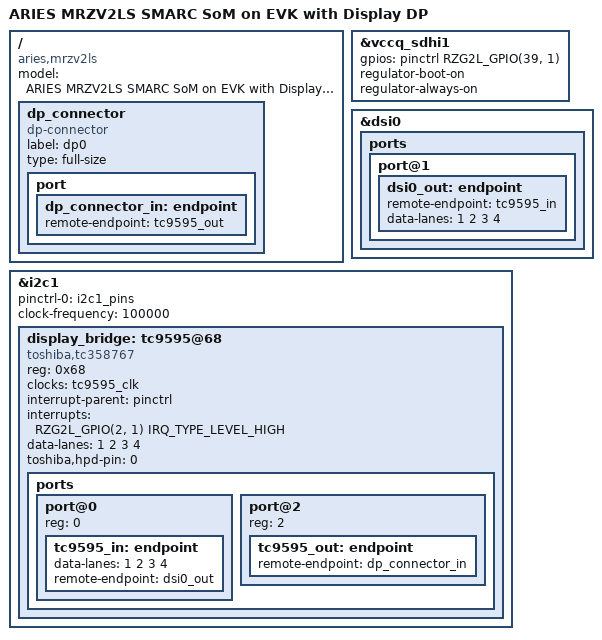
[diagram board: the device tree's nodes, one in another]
// SPDX-License-Identifier: GPL-2.0
/*
 * Device Tree Source for the MRZG2LS Single A55 SMARC SOM/CARRIER
 *
 * Copyright (C) 2021 Renesas Electronics Corp.
 * Copyright (C) 2023 ARIES Embedded
 */

/dts-v1/;
#include "../renesas/r9a07g054l2.dtsi"
#include "mrzg2ls-som.dtsi"
#include "mrzg2ls-pinfunction.dtsi"
#include "msrz-smarc-common.dtsi"
#include "mrzv2ls.dtsi"

/ {
	model = "ARIES MRZV2LS SMARC SoM on EVK with Display DP";
	compatible = "aries,mrzv2ls", "renesas,r9a07g054l2", "renesas,r9a07g054";

	dp_connector {
		compatible = "dp-connector";
		label = "dp0";
		type = "full-size";

		port {
			dp_connector_in: endpoint {
				remote-endpoint = <&tc9595_out>;
			};
		};
	};
};

&vccq_sdhi1 {
	gpios = <&pinctrl RZG2L_GPIO(39, 1) GPIO_ACTIVE_HIGH>;
	regulator-boot-on;
	regulator-always-on;
};

&dsi0 {
	status = "okay";

	ports {
		port@1 {
			dsi0_out: endpoint {
				remote-endpoint = <&tc9595_in>;
				data-lanes = <1 2 3 4>;
			};
		};
	};
};

&i2c1 {
	pinctrl-0 = <&i2c1_pins>;
	pinctrl-names = "default";
	clock-frequency = <100000>;
	status = "okay";

	display_bridge: tc9595@68 {
		compatible = "toshiba,tc358767";
		reg = <0x68>;
		clock-names = "ref";
		clocks = <&tc9595_clk>;
		interrupt-parent = <&pinctrl>;
		interrupts = <RZG2L_GPIO(2, 1) IRQ_TYPE_LEVEL_HIGH>; /* P2_1 */
		data-lanes = <1 2 3 4>;
		toshiba,hpd-pin = <0>;
		status = "okay";

		ports {
	      		#address-cells = <1>;
			#size-cells = <0>;

			port@0 {
				reg = <0>;
				tc9595_in: endpoint {
					data-lanes = <1 2 3 4>;
					remote-endpoint = <&dsi0_out>;
				};
			};

			port@2 {
				reg = <2>;
				tc9595_out: endpoint {
					remote-endpoint = <&dp_connector_in>;
				};
			};
		};
	};
};
